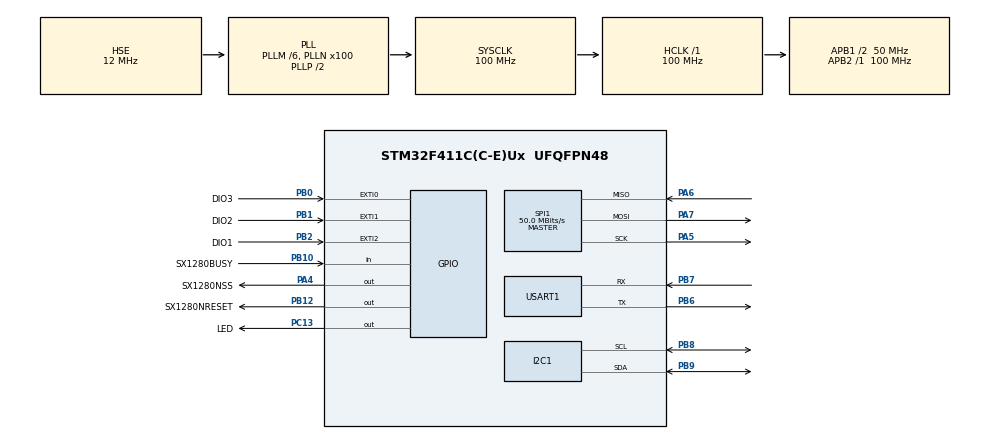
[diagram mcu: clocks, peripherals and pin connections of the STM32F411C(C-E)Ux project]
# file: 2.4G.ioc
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Dma.Request0=USART1_RX
Dma.Request1=USART1_TX
Dma.USART1_RX.0.Direction=DMA_PERIPH_TO_MEMORY
Dma.USART1_RX.0.FIFOMode=DMA_FIFOMODE_DISABLE
Dma.USART1_RX.0.Instance=DMA2_Stream2
Dma.USART1_RX.0.MemDataAlignment=DMA_MDATAALIGN_BYTE
Dma.USART1_RX.0.MemInc=DMA_MINC_ENABLE
Dma.USART1_RX.0.Mode=DMA_NORMAL
Dma.USART1_RX.0.PeriphDataAlignment=DMA_PDATAALIGN_BYTE
Dma.USART1_RX.0.PeriphInc=DMA_PINC_DISABLE
Dma.USART1_RX.0.Priority=DMA_PRIORITY_LOW
Dma.USART1_TX.1.Direction=DMA_MEMORY_TO_PERIPH
Dma.USART1_TX.1.FIFOMode=DMA_FIFOMODE_DISABLE
Dma.USART1_TX.1.Instance=DMA2_Stream7
Dma.USART1_TX.1.MemDataAlignment=DMA_MDATAALIGN_BYTE
Dma.USART1_TX.1.MemInc=DMA_MINC_ENABLE
Dma.USART1_TX.1.Mode=DMA_NORMAL
Dma.USART1_TX.1.PeriphDataAlignment=DMA_PDATAALIGN_BYTE
Dma.USART1_TX.1.PeriphInc=DMA_PINC_DISABLE
Dma.USART1_TX.1.Priority=DMA_PRIORITY_LOW
FREERTOS.Tasks01=LEDTask,8,128,StartDefaultTask,Default,NULL,Dynamic,NULL,NULL
FREERTOS.configCHECK_FOR_STACK_OVERFLOW=2
FREERTOS.configENABLE_BACKWARD_COMPATIBILITY=0
FREERTOS.configENABLE_FPU=1
FREERTOS.configRECORD_STACK_HIGH_ADDRESS=1
FREERTOS.configTOTAL_HEAP_SIZE=49152
FREERTOS.configUSE_IDLE_HOOK=0
FREERTOS.configUSE_MALLOC_FAILED_HOOK=1
Mcu.Family=STM32F4
Mcu.Name=STM32F411C(C-E)Ux
Mcu.Package=UFQFPN48
NVIC.DMA2_Stream2_IRQn=true\:5\:0\:false\:false\:true\:true\:false\:true\:true
NVIC.DMA2_Stream7_IRQn=true\:5\:0\:false\:false\:true\:true\:false\:true\:true
NVIC.EXTI0_IRQn=true\:5\:0\:false\:false\:true\:true\:true\:true\:true
NVIC.EXTI1_IRQn=true\:5\:0\:false\:false\:true\:true\:true\:true\:true
NVIC.EXTI2_IRQn=true\:5\:0\:false\:false\:true\:true\:true\:true\:true
NVIC.PriorityGroup=NVIC_PRIORITYGROUP_4
NVIC.TIM1_UP_TIM10_IRQn=true\:5\:0\:false\:false\:true\:false\:false\:true\:true
NVIC.TIM4_IRQn=true\:5\:0\:false\:false\:true\:true\:true\:true\:true
NVIC.TimeBase=TIM1_UP_TIM10_IRQn
NVIC.TimeBaseIP=TIM10
NVIC.USART1_IRQn=true\:5\:0\:false\:false\:true\:true\:true\:true\:true
PA13.Mode=Serial_Wire
PA13.Signal=SYS_JTMS-SWDIO
PA14.Mode=Serial_Wire
PA14.Signal=SYS_JTCK-SWCLK
PA4.GPIO_Label=SX1280NSS
PA4.GPIO_PuPd=GPIO_PULLUP
PA4.GPIO_Speed=GPIO_SPEED_FREQ_VERY_HIGH
PA4.PinState=GPIO_PIN_SET
PA4.Signal=GPIO_Output
PA5.Mode=Full_Duplex_Master
PA5.Signal=SPI1_SCK
PA6.Mode=Full_Duplex_Master
PA6.Signal=SPI1_MISO
PA7.Mode=Full_Duplex_Master
PA7.Signal=SPI1_MOSI
PB0.GPIO_Label=DIO3
PB0.GPIO_PuPd=GPIO_PULLDOWN
PB0.Signal=GPXTI0
PB1.GPIO_Label=DIO2
PB1.GPIO_PuPd=GPIO_PULLDOWN
PB1.Signal=GPXTI1
PB10.GPIO_Label=SX1280BUSY
PB10.Signal=GPIO_Input
PB12.GPIO_Label=SX1280NRESET
PB12.Signal=GPIO_Output
PB2.GPIO_Label=DIO1
PB2.GPIO_PuPd=GPIO_PULLDOWN
PB2.Signal=GPXTI2
PB6.Mode=Asynchronous
PB6.Signal=USART1_TX
PB7.Mode=Asynchronous
PB7.Signal=USART1_RX
PB8.Mode=I2C
PB8.Signal=I2C1_SCL
PB9.Mode=I2C
PB9.Signal=I2C1_SDA
PC13-ANTI_TAMP.GPIO_Label=LED
PC13-ANTI_TAMP.Signal=GPIO_Output
PH0\ -\ OSC_IN.Mode=HSE-External-Oscillator
PH0\ -\ OSC_IN.Signal=RCC_OSC_IN
PH1\ -\ OSC_OUT.Mode=HSE-External-Oscillator
PH1\ -\ OSC_OUT.Signal=RCC_OSC_OUT
ProjectManager.HeapSize=0x400
ProjectManager.StackSize=0x800
ProjectManager.TargetToolchain=CMake
RCC.48MHZClocksFreq_Value=50000000
RCC.AHBFreq_Value=100000000
RCC.APB1CLKDivider=RCC_HCLK_DIV2
RCC.APB1Freq_Value=50000000
RCC.APB1TimFreq_Value=100000000
RCC.APB2Freq_Value=100000000
RCC.APB2TimFreq_Value=100000000
RCC.CortexFreq_Value=100000000
RCC.HCLKFreq_Value=100000000
RCC.HSE_VALUE=12000000
RCC.HSI_VALUE=16000000
RCC.LSE_VALUE=32768
RCC.PLLM=6
RCC.PLLN=100
RCC.PLLSourceVirtual=RCC_PLLSOURCE_HSE
RCC.SYSCLKFreq_VALUE=100000000
RCC.SYSCLKSource=RCC_SYSCLKSOURCE_PLLCLK
RCC.VCOOutputFreq_Value=200000000
SPI1.CalculateBaudRate=50.0 MBits/s
SPI1.Direction=SPI_DIRECTION_2LINES
SPI1.Mode=SPI_MODE_MASTER
SPI1.VirtualType=VM_MASTER
TIM4.AutoReloadPreload=TIM_AUTORELOAD_PRELOAD_ENABLE
TIM4.Period=9999
TIM4.Prescaler=9999
USART1.VirtualMode=VM_ASYNC
VP_FREERTOS_VS_CMSIS_V2.Mode=CMSIS_V2
VP_SYS_VS_tim10.Mode=TIM10
VP_TIM4_VS_ClockSourceINT.Mode=Internal
board=custom

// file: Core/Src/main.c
/* USER CODE BEGIN Header */
/**
  ******************************************************************************
  * @file           : main.c
  * @brief          : Main program body
  ******************************************************************************
  * @attention
  *
  * Copyright (c) 2026 STMicroelectronics.
  * All rights reserved.
  *
  * This software is licensed under terms that can be found in the LICENSE file
  * in the root directory of this software component.
  * If no LICENSE file comes with this software, it is provided AS-IS.
  *
  ******************************************************************************
  */
/* USER CODE END Header */
#include "main.h"
#include "cmsis_os.h"
#include "dma.h"
#include "i2c.h"
#include "spi.h"
#include "tim.h"
#include "usart.h"
#include "gpio.h"

/* USER CODE BEGIN Includes */
/* 放在 USER CODE 段内：CubeMX 重新生成 main.c 时不会覆盖这里，
 * 而生成区的 #include 列表是按 .ioc 重建的，手加的条目会被删掉。 */
#include "HDC1080.h"
#include "SX1280.h"        /* MYSX1280_Init() 原型；缺了会触发隐式声明告警 */
#include "FreeRTOS_Task.h"
/* USER CODE END Includes */

void SystemClock_Config(void);
void MX_FREERTOS_Init(void);

int main(void)
{

  /* MCU Configuration--------------------------------------------------------*/

  /* Reset of all peripherals, Initializes the Flash interface and the Systick. */
  HAL_Init();

  /* Configure the system clock */
  SystemClock_Config();

  /* Initialize all configured peripherals */
  MX_GPIO_Init();
  MX_DMA_Init();
  MX_USART1_UART_Init();
  MX_TIM4_Init();
  MX_I2C1_Init();
  MX_SPI1_Init();
  /* USER CODE BEGIN 2 */
  /* HDC1080 初始化：此处 MX_I2C1_Init() 已执行，TIM10 时基也已在跑
   * （HDC1080_Init 内部的 HAL_Delay(15) 依赖它），但 FreeRTOS 尚未启动。
   * 返回码交给 App_SetHdcInitStatus() 记录下来，由 HDC1080Task 通过
   * 串口遥测帧的 status 字节上报，不再静默丢弃。 */
  App_SetHdcInitStatus(HDC1080_Init());

  /* SX1280 初始化：必须在这里完成 —— 也就是【任何 osThreadNew 之前】。
   * MYSX1280_Init() 内部的 SX1280_Reset() 会调用 HAL_Delay，而 HAL_Delay 依赖
   * TIM10 中断；一旦在此之前创建过 FreeRTOS 任务（例如 MX_FREERTOS_Init 里的
   * SerialModule_Init），FreeRTOS 的临界区嵌套计数就无法归零，BASEPRI 会永久停在
   * 0x50 把 TIM10 屏蔽掉，HAL_Delay 随即死等 —— 实测死机点。
   * 返回码交给 App_SetSxInitStatus() 记录，由串口上报帧体现，不静默丢弃。 */
  App_SetSxInitStatus(MYSX1280_Init());
  /* USER CODE END 2 */

  /* Init scheduler */
  osKernelInitialize();  /* Call init function for freertos objects (in cmsis_os2.c) */
  MX_FREERTOS_Init();

  /* Start scheduler */
  osKernelStart();

  /* We should never get here as control is now taken by the scheduler */

  /* Infinite loop */
  while (1)
  {

  }
}

void SystemClock_Config(void)
{
  RCC_OscInitTypeDef RCC_OscInitStruct = {0};
  RCC_ClkInitTypeDef RCC_ClkInitStruct = {0};

  /** Configure the main internal regulator output voltage
  */
  __HAL_RCC_PWR_CLK_ENABLE();
  __HAL_PWR_VOLTAGESCALING_CONFIG(PWR_REGULATOR_VOLTAGE_SCALE1);

  /** Initializes the RCC Oscillators according to the specified parameters
  * in the RCC_OscInitTypeDef structure.
  */
  RCC_OscInitStruct.OscillatorType = RCC_OSCILLATORTYPE_HSE;
  RCC_OscInitStruct.HSEState = RCC_HSE_ON;
  RCC_OscInitStruct.PLL.PLLState = RCC_PLL_ON;
  RCC_OscInitStruct.PLL.PLLSource = RCC_PLLSOURCE_HSE;
  RCC_OscInitStruct.PLL.PLLM = 6;
  RCC_OscInitStruct.PLL.PLLN = 100;
  RCC_OscInitStruct.PLL.PLLP = RCC_PLLP_DIV2;
  RCC_OscInitStruct.PLL.PLLQ = 4;
  if (HAL_RCC_OscConfig(&RCC_OscInitStruct) != HAL_OK)
  {
    Error_Handler();
  }

  /** Initializes the CPU, AHB and APB buses clocks
  */
  RCC_ClkInitStruct.ClockType = RCC_CLOCKTYPE_HCLK|RCC_CLOCKTYPE_SYSCLK
                              |RCC_CLOCKTYPE_PCLK1|RCC_CLOCKTYPE_PCLK2;
  RCC_ClkInitStruct.SYSCLKSource = RCC_SYSCLKSOURCE_PLLCLK;
  RCC_ClkInitStruct.AHBCLKDivider = RCC_SYSCLK_DIV1;
  RCC_ClkInitStruct.APB1CLKDivider = RCC_HCLK_DIV2;
  RCC_ClkInitStruct.APB2CLKDivider = RCC_HCLK_DIV1;

  if (HAL_RCC_ClockConfig(&RCC_ClkInitStruct, FLASH_LATENCY_3) != HAL_OK)
  {
    Error_Handler();
  }
}

void Error_Handler(void)
{
  __disable_irq();
  while (1)
  {
  }
}

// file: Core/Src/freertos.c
/* USER CODE BEGIN Header */
/**
  ******************************************************************************
  * File Name          : freertos.c
  * Description        : Code for freertos applications
  ******************************************************************************
  * @attention
  *
  * Copyright (c) 2026 STMicroelectronics.
  * All rights reserved.
  *
  * This software is licensed under terms that can be found in the LICENSE file
  * in the root directory of this software component.
  * If no LICENSE file comes with this software, it is provided AS-IS.
  *
  ******************************************************************************
  */
/* USER CODE END Header */

#include "FreeRTOS.h"
#include "task.h"
#include "main.h"
#include "cmsis_os.h"

/* USER CODE BEGIN Includes */
#include "serial_port.h"   /* 串口模块挂载（USART1 + DMA 空闲收帧） */
#include "app_sensor.h"    /* 应用工作流（TIM4 节拍 → 采集 → 发射 → 上报） */
/* USER CODE END Includes */

/* Definitions for LEDTask */
osThreadId_t LEDTaskHandle;
const osThreadAttr_t LEDTask_attributes = {
  .name = "LEDTask",
  .stack_size = 128 * 4,
  .priority = (osPriority_t) osPriorityLow,
};

void StartDefaultTask(void *argument);

void MX_FREERTOS_Init(void); /* (MISRA C 2004 rule 8.1) */

/* Hook prototypes */
void vApplicationStackOverflowHook(TaskHandle_t xTask, signed char *pcTaskName);
void vApplicationMallocFailedHook(void);

/* USER CODE BEGIN 4 */
void vApplicationStackOverflowHook(TaskHandle_t xTask, signed char *pcTaskName)
{
   /* Run time stack overflow checking is performed if
   configCHECK_FOR_STACK_OVERFLOW is defined to 1 or 2. This hook function is
   called if a stack overflow is detected. */
}
/* USER CODE END 4 */

/* USER CODE BEGIN 5 */
void vApplicationMallocFailedHook(void)
{
   /* vApplicationMallocFailedHook() will only be called if
   configUSE_MALLOC_FAILED_HOOK is set to 1 in FreeRTOSConfig.h. It is a hook
   function that will get called if a call to pvPortMalloc() fails.
   pvPortMalloc() is called internally by the kernel whenever a task, queue,
   timer or semaphore is created. It is also called by various parts of the
   demo application. If heap_1.c or heap_2.c are used, then the size of the
   heap available to pvPortMalloc() is defined by configTOTAL_HEAP_SIZE in
   FreeRTOSConfig.h, and the xPortGetFreeHeapSize() API function can be used
   to query the size of free heap space that remains (although it does not
   provide information on how the remaining heap might be fragmented). */
}
/* USER CODE END 5 */

void MX_FREERTOS_Init(void) {

  /* Create the thread(s) */
  /* creation of LEDTask */
  LEDTaskHandle = osThreadNew(StartDefaultTask, NULL, &LEDTask_attributes);

  /* USER CODE BEGIN RTOS_THREADS */
  /* add threads, ... */
  /* 串口模块必须先初始化：内部会创建模块调度线程并启动 USART1 的 DMA 空闲接收。
   * 此处位于 osKernelInitialize() 之后、osKernelStart() 之前，满足模块要求。 */
  if (!SerialPort_Init()) {
    Error_Handler();
  }

  /* 应用工作流：创建 TIM4 节拍信号量与 SensorTask；
   * HDC1080 / SX1280 的实际初始化在任务内完成（避免调度器启动前长时间阻塞）。 */
  App_Sensor_Init();
  /* USER CODE END RTOS_THREADS */

}

void StartDefaultTask(void *argument)
{
  for(;;)
  {
    osDelay(1);
  }
}
